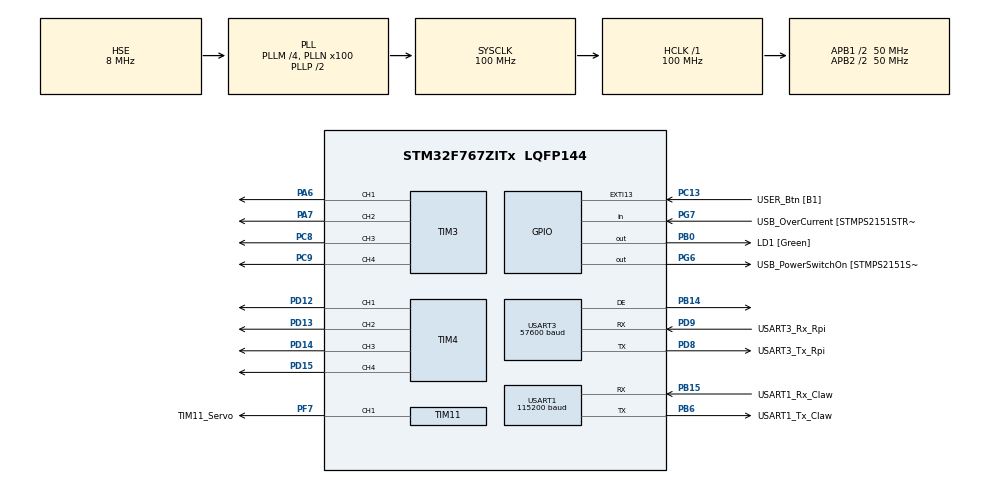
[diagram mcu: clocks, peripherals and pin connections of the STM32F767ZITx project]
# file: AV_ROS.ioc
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Dma.Request0=USART3_RX
Dma.Request1=USART3_TX
Dma.USART3_RX.0.Direction=DMA_PERIPH_TO_MEMORY
Dma.USART3_RX.0.FIFOMode=DMA_FIFOMODE_DISABLE
Dma.USART3_RX.0.Instance=DMA1_Stream1
Dma.USART3_RX.0.MemDataAlignment=DMA_MDATAALIGN_BYTE
Dma.USART3_RX.0.MemInc=DMA_MINC_ENABLE
Dma.USART3_RX.0.Mode=DMA_NORMAL
Dma.USART3_RX.0.PeriphDataAlignment=DMA_PDATAALIGN_BYTE
Dma.USART3_RX.0.PeriphInc=DMA_PINC_DISABLE
Dma.USART3_RX.0.Priority=DMA_PRIORITY_MEDIUM
Dma.USART3_TX.1.Direction=DMA_MEMORY_TO_PERIPH
Dma.USART3_TX.1.FIFOMode=DMA_FIFOMODE_DISABLE
Dma.USART3_TX.1.Instance=DMA1_Stream3
Dma.USART3_TX.1.MemDataAlignment=DMA_MDATAALIGN_BYTE
Dma.USART3_TX.1.MemInc=DMA_MINC_ENABLE
Dma.USART3_TX.1.Mode=DMA_NORMAL
Dma.USART3_TX.1.PeriphDataAlignment=DMA_PDATAALIGN_BYTE
Dma.USART3_TX.1.PeriphInc=DMA_PINC_DISABLE
Dma.USART3_TX.1.Priority=DMA_PRIORITY_MEDIUM
Mcu.Family=STM32F7
Mcu.Name=STM32F767ZITx
Mcu.Package=LQFP144
NVIC.DMA1_Stream1_IRQn=true\:0\:0\:false\:false\:true\:false\:true\:true
NVIC.DMA1_Stream3_IRQn=true\:0\:0\:false\:false\:true\:false\:true\:true
NVIC.PriorityGroup=NVIC_PRIORITYGROUP_4
NVIC.TIM1_TRG_COM_TIM11_IRQn=true\:0\:0\:false\:false\:true\:true\:true\:true
NVIC.TIM3_IRQn=true\:0\:0\:false\:false\:true\:true\:true\:true
NVIC.TIM4_IRQn=true\:0\:0\:false\:false\:true\:true\:true\:true
NVIC.USART1_IRQn=true\:0\:0\:false\:false\:true\:true\:true\:true
NVIC.USART3_IRQn=true\:0\:0\:false\:false\:true\:true\:true\:true
PA1.GPIO_Label=RMII_REF_CLK [LAN8742A-CZ-TR_REFCLK0]
PA1.Signal=ETH_REF_CLK
PA11.GPIO_Label=USB_DM
PA11.Signal=USB_OTG_FS_DM
PA12.GPIO_Label=USB_DP
PA12.Signal=USB_OTG_FS_DP
PA13.GPIO_Label=TMS
PA13.Signal=SYS_JTMS-SWDIO
PA14.GPIO_Label=TCK
PA14.Signal=SYS_JTCK-SWCLK
PA2.GPIO_Label=RMII_MDIO [LAN8742A-CZ-TR_MDIO]
PA2.Signal=ETH_MDIO
PA6.Signal=S_TIM3_CH1
PA7.Signal=S_TIM3_CH2
PA8.GPIO_Label=USB_SOF [TP1]
PA8.Signal=USB_OTG_FS_SOF
PB0.GPIO_Label=LD1 [Green]
PB0.Signal=GPIO_Output
PB13.GPIO_Label=RMII_TXD1 [LAN8742A-CZ-TR_TXD1]
PB13.Signal=ETH_TXD1
PB14.Mode=Hardware Flow Control (RS485)
PB14.Signal=USART3_DE
PB15.GPIO_Label=USART1_Rx_Claw
PB15.Mode=Asynchronous
PB15.Signal=USART1_RX
PB3.GPIO_Label=SW0
PB3.Signal=SYS_JTDO-SWO
PB6.GPIO_Label=USART1_Tx_Claw
PB6.Mode=Asynchronous
PB6.Signal=USART1_TX
PC1.GPIO_Label=RMII_MDC [LAN8742A-CZ-TR_MDC]
PC1.Signal=ETH_MDC
PC13.GPIO_Label=USER_Btn [B1]
PC13.Signal=GPXTI13
PC14/OSC32_IN.Signal=RCC_OSC32_IN
PC15/OSC32_OUT.Signal=RCC_OSC32_OUT
PC4.GPIO_Label=RMII_RXD0 [LAN8742A-CZ-TR_RXD0]
PC4.Signal=ETH_RXD0
PC5.GPIO_Label=RMII_RXD1 [LAN8742A-CZ-TR_RXD1]
PC5.Signal=ETH_RXD1
PC8.Signal=S_TIM3_CH3
PC9.Signal=S_TIM3_CH4
PD12.Signal=S_TIM4_CH1
PD13.Signal=S_TIM4_CH2
PD14.Signal=S_TIM4_CH3
PD15.Signal=S_TIM4_CH4
PD6.Signal=USART2_RX
PD8.GPIO_Label=USART3_Tx_Rpi
PD8.Mode=Asynchronous
PD8.Signal=USART3_TX
PD9.GPIO_Label=USART3_Rx_Rpi
PD9.Mode=Asynchronous
PD9.Signal=USART3_RX
PF7.GPIO_Label=TIM11_Servo
PF7.Signal=S_TIM11_CH1
PG11.GPIO_Label=RMII_TX_EN [LAN8742A-CZ-TR_TXEN]
PG11.Signal=ETH_TX_EN
PG13.GPIO_Label=RMII_TXD0 [LAN8742A-CZ-TR_TXD0]
PG13.Signal=ETH_TXD0
PG6.GPIO_Label=USB_PowerSwitchOn [STMPS2151STR_EN]
PG6.Signal=GPIO_Output
PG7.GPIO_Label=USB_OverCurrent [STMPS2151STR_FAULT]
PG7.Signal=GPIO_Input
PH0/OSC_IN.GPIO_Label=MCO [STM32F103CBT6_PA8]
PH0/OSC_IN.Mode=HSE-External-Oscillator
PH0/OSC_IN.Signal=RCC_OSC_IN
PH1/OSC_OUT.Mode=HSE-External-Oscillator
PH1/OSC_OUT.Signal=RCC_OSC_OUT
ProjectManager.HeapSize=0x200
ProjectManager.StackSize=0x400
ProjectManager.TargetToolchain=STM32CubeIDE
RCC.48MHZClocksFreq_Value=24000000
RCC.AHBFreq_Value=100000000
RCC.APB1CLKDivider=RCC_HCLK_DIV2
RCC.APB1Freq_Value=50000000
RCC.APB1TimFreq_Value=100000000
RCC.APB2CLKDivider=RCC_HCLK_DIV2
RCC.APB2Freq_Value=50000000
RCC.APB2TimFreq_Value=100000000
RCC.CortexFreq_Value=100000000
RCC.HCLKFreq_Value=100000000
RCC.HSE_VALUE=8000000
RCC.HSI_VALUE=16000000
RCC.LSE_VALUE=32768
RCC.PLLM=4
RCC.PLLMUL=RCC_PLL_MUL9
RCC.PLLN=100
RCC.PLLSourceVirtual=RCC_PLLSOURCE_HSE
RCC.PRESCALERUSB=RCC_USBCLKSOURCE_PLL_DIV1_5
RCC.SYSCLKFreq_VALUE=100000000
RCC.SYSCLKSource=RCC_SYSCLKSOURCE_PLLCLK
RCC.SYSCLKSourceVirtual=RCC_SYSCLKSOURCE_PLLCLK
RCC.USBFreq_Value=100000000
RCC.VCOOutputFreq_Value=200000000
SH.S_TIM11_CH1.0=TIM11_CH1,PWM Generation1 CH1
SH.S_TIM3_CH1.0=TIM3_CH1,PWM Generation1 CH1
SH.S_TIM3_CH2.0=TIM3_CH2,PWM Generation2 CH2
SH.S_TIM3_CH3.0=TIM3_CH3,PWM Generation3 CH3
SH.S_TIM3_CH4.0=TIM3_CH4,PWM Generation4 CH4
SH.S_TIM4_CH1.0=TIM4_CH1,PWM Generation1 CH1
SH.S_TIM4_CH2.0=TIM4_CH2,PWM Generation2 CH2
SH.S_TIM4_CH3.0=TIM4_CH3,PWM Generation3 CH3
SH.S_TIM4_CH4.0=TIM4_CH4,PWM Generation4 CH4
TIM11.Channel=TIM_CHANNEL_1
TIM11.Period=19999
TIM11.Prescaler=99
TIM3.Channel-PWM\ Generation1\ CH1=TIM_CHANNEL_1
TIM3.Channel-PWM\ Generation2\ CH2=TIM_CHANNEL_2
TIM3.Channel-PWM\ Generation3\ CH3=TIM_CHANNEL_3
TIM3.Channel-PWM\ Generation4\ CH4=TIM_CHANNEL_4
TIM4.Channel-PWM\ Generation1\ CH1=TIM_CHANNEL_1
TIM4.Channel-PWM\ Generation2\ CH2=TIM_CHANNEL_2
TIM4.Channel-PWM\ Generation3\ CH3=TIM_CHANNEL_3
TIM4.Channel-PWM\ Generation4\ CH4=TIM_CHANNEL_4
USART1.BaudRate=115200
USART1.VirtualMode-Asynchronous=VM_ASYNC
USART3.BaudRate=57600
USART3.VirtualMode-Asynchronous=VM_ASYNC
USART3.VirtualMode-Hardware\ Flow\ Control\ (RS485)=VM_ASYNC
VP_TIM11_VS_ClockSourceINT.Mode=Enable_Timer
VP_TIM3_VS_ClockSourceINT.Mode=Internal
VP_TIM4_VS_ClockSourceINT.Mode=Internal
board=NUCLEO-F767ZI

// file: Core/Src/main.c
/* USER CODE BEGIN Header */
/**
  ******************************************************************************
  * @file           : main.c
  * @brief          : Main program body
  ******************************************************************************
  * @attention
  *
  * Copyright (c) 2022 STMicroelectronics.
  * All rights reserved.
  *
  * This software is licensed under terms that can be found in the LICENSE file
  * in the root directory of this software component.
  * If no LICENSE file comes with this software, it is provided AS-IS.
  *
  ******************************************************************************
  */
/* USER CODE END Header */
#include "main.h"

/* USER CODE BEGIN Includes */
#include "mainpp.h"
/* USER CODE END Includes */

TIM_HandleTypeDef htim3;
TIM_HandleTypeDef htim4;
TIM_HandleTypeDef htim11;

UART_HandleTypeDef huart1;
UART_HandleTypeDef huart3;
DMA_HandleTypeDef hdma_usart3_rx;
DMA_HandleTypeDef hdma_usart3_tx;

void SystemClock_Config(void);
static void MX_GPIO_Init(void);
static void MX_DMA_Init(void);
static void MX_USART1_UART_Init(void);
static void MX_USART3_UART_Init(void);
static void MX_TIM11_Init(void);
static void MX_TIM3_Init(void);
static void MX_TIM4_Init(void);

int main(void)
{

  /* MCU Configuration--------------------------------------------------------*/

  /* Reset of all peripherals, Initializes the Flash interface and the Systick. */
  HAL_Init();

  /* Configure the system clock */
  SystemClock_Config();

  /* Initialize all configured peripherals */
  MX_GPIO_Init();
  MX_DMA_Init();
  MX_USART1_UART_Init();
  MX_USART3_UART_Init();
  MX_TIM11_Init();
  MX_TIM3_Init();
  MX_TIM4_Init();
  /* USER CODE BEGIN 2 */
//  setup();
  HAL_TIM_PWM_Start(&htim3, TIM_CHANNEL_1);
  HAL_TIM_PWM_Start(&htim3, TIM_CHANNEL_2);
  int duty = 80;
  /* USER CODE END 2 */

  /* Infinite loop */
  /* USER CODE BEGIN WHILE */
  while (1)
  {
//	  loop();
	__HAL_TIM_SET_COMPARE(&htim3,TIM_CHANNEL_1, duty*400);
	__HAL_TIM_SET_COMPARE(&htim3,TIM_CHANNEL_2, duty*400);
    /* USER CODE END WHILE */

  }
}

void SystemClock_Config(void)
{
  RCC_OscInitTypeDef RCC_OscInitStruct = {0};
  RCC_ClkInitTypeDef RCC_ClkInitStruct = {0};

  /** Configure the main internal regulator output voltage
  */
  __HAL_RCC_PWR_CLK_ENABLE();
  __HAL_PWR_VOLTAGESCALING_CONFIG(PWR_REGULATOR_VOLTAGE_SCALE3);

  /** Initializes the RCC Oscillators according to the specified parameters
  * in the RCC_OscInitTypeDef structure.
  */
  RCC_OscInitStruct.OscillatorType = RCC_OSCILLATORTYPE_HSE;
  RCC_OscInitStruct.HSEState = RCC_HSE_ON;
  RCC_OscInitStruct.PLL.PLLState = RCC_PLL_ON;
  RCC_OscInitStruct.PLL.PLLSource = RCC_PLLSOURCE_HSE;
  RCC_OscInitStruct.PLL.PLLM = 4;
  RCC_OscInitStruct.PLL.PLLN = 100;
  RCC_OscInitStruct.PLL.PLLP = RCC_PLLP_DIV2;
  RCC_OscInitStruct.PLL.PLLQ = 2;
  RCC_OscInitStruct.PLL.PLLR = 2;
  if (HAL_RCC_OscConfig(&RCC_OscInitStruct) != HAL_OK)
  {
    Error_Handler();
  }

  /** Activate the Over-Drive mode
  */
  if (HAL_PWREx_EnableOverDrive() != HAL_OK)
  {
    Error_Handler();
  }

  /** Initializes the CPU, AHB and APB buses clocks
  */
  RCC_ClkInitStruct.ClockType = RCC_CLOCKTYPE_HCLK|RCC_CLOCKTYPE_SYSCLK
                              |RCC_CLOCKTYPE_PCLK1|RCC_CLOCKTYPE_PCLK2;
  RCC_ClkInitStruct.SYSCLKSource = RCC_SYSCLKSOURCE_PLLCLK;
  RCC_ClkInitStruct.AHBCLKDivider = RCC_SYSCLK_DIV1;
  RCC_ClkInitStruct.APB1CLKDivider = RCC_HCLK_DIV2;
  RCC_ClkInitStruct.APB2CLKDivider = RCC_HCLK_DIV2;

  if (HAL_RCC_ClockConfig(&RCC_ClkInitStruct, FLASH_LATENCY_3) != HAL_OK)
  {
    Error_Handler();
  }
}

static void MX_TIM3_Init(void)
{

  TIM_ClockConfigTypeDef sClockSourceConfig = {0};
  TIM_MasterConfigTypeDef sMasterConfig = {0};
  TIM_OC_InitTypeDef sConfigOC = {0};

  htim3.Instance = TIM3;
  htim3.Init.Prescaler = 0;
  htim3.Init.CounterMode = TIM_COUNTERMODE_UP;
  htim3.Init.Period = 65535;
  htim3.Init.ClockDivision = TIM_CLOCKDIVISION_DIV1;
  htim3.Init.AutoReloadPreload = TIM_AUTORELOAD_PRELOAD_DISABLE;
  if (HAL_TIM_Base_Init(&htim3) != HAL_OK)
  {
    Error_Handler();
  }
  sClockSourceConfig.ClockSource = TIM_CLOCKSOURCE_INTERNAL;
  if (HAL_TIM_ConfigClockSource(&htim3, &sClockSourceConfig) != HAL_OK)
  {
    Error_Handler();
  }
  if (HAL_TIM_PWM_Init(&htim3) != HAL_OK)
  {
    Error_Handler();
  }
  sMasterConfig.MasterOutputTrigger = TIM_TRGO_RESET;
  sMasterConfig.MasterSlaveMode = TIM_MASTERSLAVEMODE_DISABLE;
  if (HAL_TIMEx_MasterConfigSynchronization(&htim3, &sMasterConfig) != HAL_OK)
  {
    Error_Handler();
  }
  sConfigOC.OCMode = TIM_OCMODE_PWM1;
  sConfigOC.Pulse = 0;
  sConfigOC.OCPolarity = TIM_OCPOLARITY_HIGH;
  sConfigOC.OCFastMode = TIM_OCFAST_DISABLE;
  if (HAL_TIM_PWM_ConfigChannel(&htim3, &sConfigOC, TIM_CHANNEL_1) != HAL_OK)
  {
    Error_Handler();
  }
  if (HAL_TIM_PWM_ConfigChannel(&htim3, &sConfigOC, TIM_CHANNEL_2) != HAL_OK)
  {
    Error_Handler();
  }
  if (HAL_TIM_PWM_ConfigChannel(&htim3, &sConfigOC, TIM_CHANNEL_3) != HAL_OK)
  {
    Error_Handler();
  }
  if (HAL_TIM_PWM_ConfigChannel(&htim3, &sConfigOC, TIM_CHANNEL_4) != HAL_OK)
  {
    Error_Handler();
  }
  HAL_TIM_MspPostInit(&htim3);

}

static void MX_TIM4_Init(void)
{

  TIM_ClockConfigTypeDef sClockSourceConfig = {0};
  TIM_MasterConfigTypeDef sMasterConfig = {0};
  TIM_OC_InitTypeDef sConfigOC = {0};

  htim4.Instance = TIM4;
  htim4.Init.Prescaler = 0;
  htim4.Init.CounterMode = TIM_COUNTERMODE_UP;
  htim4.Init.Period = 65535;
  htim4.Init.ClockDivision = TIM_CLOCKDIVISION_DIV1;
  htim4.Init.AutoReloadPreload = TIM_AUTORELOAD_PRELOAD_DISABLE;
  if (HAL_TIM_Base_Init(&htim4) != HAL_OK)
  {
    Error_Handler();
  }
  sClockSourceConfig.ClockSource = TIM_CLOCKSOURCE_INTERNAL;
  if (HAL_TIM_ConfigClockSource(&htim4, &sClockSourceConfig) != HAL_OK)
  {
    Error_Handler();
  }
  if (HAL_TIM_PWM_Init(&htim4) != HAL_OK)
  {
    Error_Handler();
  }
  sMasterConfig.MasterOutputTrigger = TIM_TRGO_RESET;
  sMasterConfig.MasterSlaveMode = TIM_MASTERSLAVEMODE_DISABLE;
  if (HAL_TIMEx_MasterConfigSynchronization(&htim4, &sMasterConfig) != HAL_OK)
  {
    Error_Handler();
  }
  sConfigOC.OCMode = TIM_OCMODE_PWM1;
  sConfigOC.Pulse = 0;
  sConfigOC.OCPolarity = TIM_OCPOLARITY_HIGH;
  sConfigOC.OCFastMode = TIM_OCFAST_DISABLE;
  if (HAL_TIM_PWM_ConfigChannel(&htim4, &sConfigOC, TIM_CHANNEL_1) != HAL_OK)
  {
    Error_Handler();
  }
  if (HAL_TIM_PWM_ConfigChannel(&htim4, &sConfigOC, TIM_CHANNEL_2) != HAL_OK)
  {
    Error_Handler();
  }
  if (HAL_TIM_PWM_ConfigChannel(&htim4, &sConfigOC, TIM_CHANNEL_3) != HAL_OK)
  {
    Error_Handler();
  }
  if (HAL_TIM_PWM_ConfigChannel(&htim4, &sConfigOC, TIM_CHANNEL_4) != HAL_OK)
  {
    Error_Handler();
  }
  HAL_TIM_MspPostInit(&htim4);

}

static void MX_TIM11_Init(void)
{

  TIM_OC_InitTypeDef sConfigOC = {0};

  htim11.Instance = TIM11;
  htim11.Init.Prescaler = 99;
  htim11.Init.CounterMode = TIM_COUNTERMODE_UP;
  htim11.Init.Period = 19999;
  htim11.Init.ClockDivision = TIM_CLOCKDIVISION_DIV1;
  htim11.Init.AutoReloadPreload = TIM_AUTORELOAD_PRELOAD_DISABLE;
  if (HAL_TIM_Base_Init(&htim11) != HAL_OK)
  {
    Error_Handler();
  }
  if (HAL_TIM_PWM_Init(&htim11) != HAL_OK)
  {
    Error_Handler();
  }
  sConfigOC.OCMode = TIM_OCMODE_PWM1;
  sConfigOC.Pulse = 0;
  sConfigOC.OCPolarity = TIM_OCPOLARITY_HIGH;
  sConfigOC.OCFastMode = TIM_OCFAST_DISABLE;
  if (HAL_TIM_PWM_ConfigChannel(&htim11, &sConfigOC, TIM_CHANNEL_1) != HAL_OK)
  {
    Error_Handler();
  }
  HAL_TIM_MspPostInit(&htim11);

}

static void MX_USART1_UART_Init(void)
{

  huart1.Instance = USART1;
  huart1.Init.BaudRate = 115200;
  huart1.Init.WordLength = UART_WORDLENGTH_8B;
  huart1.Init.StopBits = UART_STOPBITS_1;
  huart1.Init.Parity = UART_PARITY_NONE;
  huart1.Init.Mode = UART_MODE_TX_RX;
  huart1.Init.HwFlowCtl = UART_HWCONTROL_NONE;
  huart1.Init.OverSampling = UART_OVERSAMPLING_16;
  huart1.Init.OneBitSampling = UART_ONE_BIT_SAMPLE_DISABLE;
  huart1.AdvancedInit.AdvFeatureInit = UART_ADVFEATURE_NO_INIT;
  if (HAL_UART_Init(&huart1) != HAL_OK)
  {
    Error_Handler();
  }

}

static void MX_USART3_UART_Init(void)
{

  huart3.Instance = USART3;
  huart3.Init.BaudRate = 57600;
  huart3.Init.WordLength = UART_WORDLENGTH_8B;
  huart3.Init.StopBits = UART_STOPBITS_1;
  huart3.Init.Parity = UART_PARITY_NONE;
  huart3.Init.Mode = UART_MODE_TX_RX;
  huart3.Init.HwFlowCtl = UART_HWCONTROL_NONE;
  huart3.Init.OverSampling = UART_OVERSAMPLING_16;
  huart3.Init.OneBitSampling = UART_ONE_BIT_SAMPLE_DISABLE;
  huart3.AdvancedInit.AdvFeatureInit = UART_ADVFEATURE_NO_INIT;
  if (HAL_RS485Ex_Init(&huart3, UART_DE_POLARITY_HIGH, 0, 0) != HAL_OK)
  {
    Error_Handler();
  }

}

static void MX_DMA_Init(void)
{

  /* DMA controller clock enable */
  __HAL_RCC_DMA1_CLK_ENABLE();

  /* DMA interrupt init */
  /* DMA1_Stream1_IRQn interrupt configuration */
  HAL_NVIC_SetPriority(DMA1_Stream1_IRQn, 0, 0);
  HAL_NVIC_EnableIRQ(DMA1_Stream1_IRQn);
  /* DMA1_Stream3_IRQn interrupt configuration */
  HAL_NVIC_SetPriority(DMA1_Stream3_IRQn, 0, 0);
  HAL_NVIC_EnableIRQ(DMA1_Stream3_IRQn);

}

static void MX_GPIO_Init(void)
{
  GPIO_InitTypeDef GPIO_InitStruct = {0};

  /* GPIO Ports Clock Enable */
  __HAL_RCC_GPIOC_CLK_ENABLE();
  __HAL_RCC_GPIOF_CLK_ENABLE();
  __HAL_RCC_GPIOH_CLK_ENABLE();
  __HAL_RCC_GPIOA_CLK_ENABLE();
  __HAL_RCC_GPIOB_CLK_ENABLE();
  __HAL_RCC_GPIOD_CLK_ENABLE();
  __HAL_RCC_GPIOG_CLK_ENABLE();

  /*Configure GPIO pin Output Level */
  HAL_GPIO_WritePin(LD1_GPIO_Port, LD1_Pin, GPIO_PIN_RESET);

  /*Configure GPIO pin Output Level */
  HAL_GPIO_WritePin(USB_PowerSwitchOn_GPIO_Port, USB_PowerSwitchOn_Pin, GPIO_PIN_RESET);

  /*Configure GPIO pin : USER_Btn_Pin */
  GPIO_InitStruct.Pin = USER_Btn_Pin;
  GPIO_InitStruct.Mode = GPIO_MODE_IT_RISING;
  GPIO_InitStruct.Pull = GPIO_NOPULL;
  HAL_GPIO_Init(USER_Btn_GPIO_Port, &GPIO_InitStruct);

  /*Configure GPIO pins : RMII_MDC_Pin RMII_RXD0_Pin RMII_RXD1_Pin */
  GPIO_InitStruct.Pin = RMII_MDC_Pin|RMII_RXD0_Pin|RMII_RXD1_Pin;
  GPIO_InitStruct.Mode = GPIO_MODE_AF_PP;
  GPIO_InitStruct.Pull = GPIO_NOPULL;
  GPIO_InitStruct.Speed = GPIO_SPEED_FREQ_VERY_HIGH;
  GPIO_InitStruct.Alternate = GPIO_AF11_ETH;
  HAL_GPIO_Init(GPIOC, &GPIO_InitStruct);

  /*Configure GPIO pins : RMII_REF_CLK_Pin RMII_MDIO_Pin */
  GPIO_InitStruct.Pin = RMII_REF_CLK_Pin|RMII_MDIO_Pin;
  GPIO_InitStruct.Mode = GPIO_MODE_AF_PP;
  GPIO_InitStruct.Pull = GPIO_NOPULL;
  GPIO_InitStruct.Speed = GPIO_SPEED_FREQ_VERY_HIGH;
  GPIO_InitStruct.Alternate = GPIO_AF11_ETH;
  HAL_GPIO_Init(GPIOA, &GPIO_InitStruct);

  /*Configure GPIO pin : LD1_Pin */
  GPIO_InitStruct.Pin = LD1_Pin;
  GPIO_InitStruct.Mode = GPIO_MODE_OUTPUT_PP;
  GPIO_InitStruct.Pull = GPIO_NOPULL;
  GPIO_InitStruct.Speed = GPIO_SPEED_FREQ_LOW;
  HAL_GPIO_Init(LD1_GPIO_Port, &GPIO_InitStruct);

  /*Configure GPIO pin : RMII_TXD1_Pin */
  GPIO_InitStruct.Pin = RMII_TXD1_Pin;
  GPIO_InitStruct.Mode = GPIO_MODE_AF_PP;
  GPIO_InitStruct.Pull = GPIO_NOPULL;
  GPIO_InitStruct.Speed = GPIO_SPEED_FREQ_VERY_HIGH;
  GPIO_InitStruct.Alternate = GPIO_AF11_ETH;
  HAL_GPIO_Init(RMII_TXD1_GPIO_Port, &GPIO_InitStruct);

  /*Configure GPIO pin : USB_PowerSwitchOn_Pin */
  GPIO_InitStruct.Pin = USB_PowerSwitchOn_Pin;
  GPIO_InitStruct.Mode = GPIO_MODE_OUTPUT_PP;
  GPIO_InitStruct.Pull = GPIO_NOPULL;
  GPIO_InitStruct.Speed = GPIO_SPEED_FREQ_LOW;
  HAL_GPIO_Init(USB_PowerSwitchOn_GPIO_Port, &GPIO_InitStruct);

  /*Configure GPIO pin : USB_OverCurrent_Pin */
  GPIO_InitStruct.Pin = USB_OverCurrent_Pin;
  GPIO_InitStruct.Mode = GPIO_MODE_INPUT;
  GPIO_InitStruct.Pull = GPIO_NOPULL;
  HAL_GPIO_Init(USB_OverCurrent_GPIO_Port, &GPIO_InitStruct);

  /*Configure GPIO pins : USB_SOF_Pin USB_DM_Pin USB_DP_Pin */
  GPIO_InitStruct.Pin = USB_SOF_Pin|USB_DM_Pin|USB_DP_Pin;
  GPIO_InitStruct.Mode = GPIO_MODE_AF_PP;
  GPIO_InitStruct.Pull = GPIO_NOPULL;
  GPIO_InitStruct.Speed = GPIO_SPEED_FREQ_VERY_HIGH;
  GPIO_InitStruct.Alternate = GPIO_AF10_OTG_FS;
  HAL_GPIO_Init(GPIOA, &GPIO_InitStruct);

  /*Configure GPIO pin : PD6 */
  GPIO_InitStruct.Pin = GPIO_PIN_6;
  GPIO_InitStruct.Mode = GPIO_MODE_AF_PP;
  GPIO_InitStruct.Pull = GPIO_NOPULL;
  GPIO_InitStruct.Speed = GPIO_SPEED_FREQ_VERY_HIGH;
  GPIO_InitStruct.Alternate = GPIO_AF7_USART2;
  HAL_GPIO_Init(GPIOD, &GPIO_InitStruct);

  /*Configure GPIO pins : RMII_TX_EN_Pin RMII_TXD0_Pin */
  GPIO_InitStruct.Pin = RMII_TX_EN_Pin|RMII_TXD0_Pin;
  GPIO_InitStruct.Mode = GPIO_MODE_AF_PP;
  GPIO_InitStruct.Pull = GPIO_NOPULL;
  GPIO_InitStruct.Speed = GPIO_SPEED_FREQ_VERY_HIGH;
  GPIO_InitStruct.Alternate = GPIO_AF11_ETH;
  HAL_GPIO_Init(GPIOG, &GPIO_InitStruct);

}

void Error_Handler(void)
{
  __disable_irq();
  while (1)
  {
  }
}
